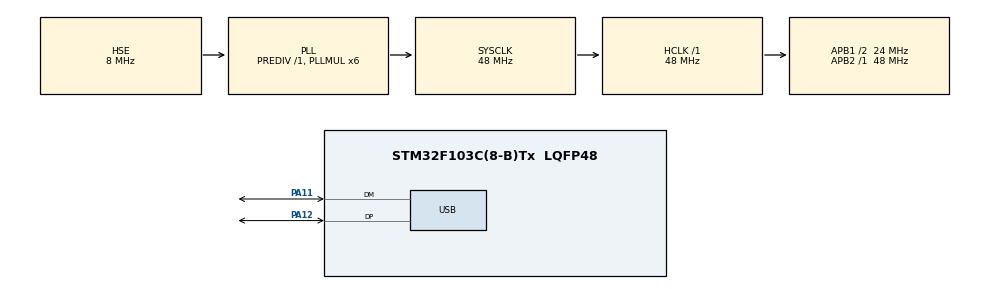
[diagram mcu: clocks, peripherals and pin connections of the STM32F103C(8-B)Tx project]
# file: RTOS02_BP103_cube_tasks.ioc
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Mcu.Family=STM32F1
USB_DEVICE.CLASS_NAME_FS=CDC
PD1-OSC_OUT.Mode=HSE-External-Oscillator
USB_DEVICE.VirtualModeFS=Cdc_FS
PA11.Mode=Device
PD0-OSC_IN.Signal=RCC_OSC_IN
RCC.APB1CLKDivider=RCC_HCLK_DIV2
VP_SYS_VS_ND.Mode=No_Debug
RCC.SYSCLKSource=RCC_SYSCLKSOURCE_PLLCLK
ProjectManager.StackSize=0x400
PD1-OSC_OUT.Signal=RCC_OSC_OUT
PA12.Signal=USB_DP
VP_SYS_VS_tim3.Mode=TIM3
ProjectManager.TargetToolchain=STM32CubeIDE
RCC.HCLKFreq_Value=48000000
VP_USB_DEVICE_VS_USB_DEVICE_CDC_FS.Mode=CDC_FS
RCC.APB2TimFreq_Value=48000000
RCC.USBFreq_Value=48000000
RCC.AHBFreq_Value=48000000
PD0-OSC_IN.Mode=HSE-External-Oscillator
board=custom
RCC.PLLMUL=RCC_PLL_MUL6
NVIC.TIM3_IRQn=true\:0\:0\:false\:false\:true\:false\:true
RCC.APB2Freq_Value=48000000
NVIC.USB_LP_CAN1_RX0_IRQn=true\:0\:0\:false\:false\:true\:false\:true
Mcu.Name=STM32F103C(8-B)Tx
RCC.SYSCLKFreq_VALUE=48000000
Mcu.Package=LQFP48
NVIC.TimeBase=TIM3_IRQn
PA12.Mode=Device
PA11.Signal=USB_DM
NVIC.TimeBaseIP=TIM3
ProjectManager.HeapSize=0x200
NVIC.PriorityGroup=NVIC_PRIORITYGROUP_4
RCC.APB1TimFreq_Value=48000000
RCC.APB1Freq_Value=24000000
USB_DEVICE.VirtualMode=Cdc

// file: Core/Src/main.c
/* USER CODE BEGIN Header */
/**
  ******************************************************************************
  * @file           : main.c
  * @brief          : Main program body
  ******************************************************************************
  * @attention
  *
  * <h2><center>&copy; Copyright (c) 2021 STMicroelectronics.
  * All rights reserved.</center></h2>
  *
  * This software component is licensed by ST under BSD 3-Clause license,
  * the "License"; You may not use this file except in compliance with the
  * License. You may obtain a copy of the License at:
  *                        opensource.org/licenses/BSD-3-Clause
  *
  ******************************************************************************
  */
/* USER CODE END Header */
#include "main.h"
#include "usb_device.h"

/* USER CODE BEGIN Includes */
//#include <stdio.h>
#include "FreeRTOS.h"
#include "task.h"

/* USER CODE END Includes */

void SystemClock_Config(void);
static void MX_GPIO_Init(void);
/* USER CODE BEGIN PFP */

static void task1_handler(void* parameter);
static void task2_handler(void* parameter);
//extern void initialise_monitor_handles(void);

/* USER CODE END PFP */

int main(void)
{
  /* USER CODE BEGIN 1 */

	TaskHandle_t task1_handle;
	TaskHandle_t task2_handle;

	BaseType_t status;

  /* USER CODE END 1 */

  /* MCU Configuration--------------------------------------------------------*/

  /* Reset of all peripherals, Initializes the Flash interface and the Systick. */
  HAL_Init();

  /* Configure the system clock */
  SystemClock_Config();

  /* Initialize all configured peripherals */
  MX_GPIO_Init();
  MX_USB_DEVICE_Init();
  /* USER CODE BEGIN 2 */

//  initialise_monitor_handles();

  status = xTaskCreate(task1_handler, "Task-1", 200, "Task-1\n", 2, &task1_handle);

  configASSERT(status == pdPASS);

  status = xTaskCreate(task2_handler, "Task-2", 200, "Task-2\n", 2, &task2_handle);

  configASSERT(status == pdPASS);

  vTaskStartScheduler();

  // if the control comes here, then the launch of the
  // scheduler has failed due to insufficient memory

  /* USER CODE END 2 */

  /* Infinite loop */
  while (1)
  {

  }
}

void SystemClock_Config(void)
{
  RCC_OscInitTypeDef RCC_OscInitStruct = {0};
  RCC_ClkInitTypeDef RCC_ClkInitStruct = {0};
  RCC_PeriphCLKInitTypeDef PeriphClkInit = {0};

  /** Initializes the RCC Oscillators according to the specified parameters
  * in the RCC_OscInitTypeDef structure.
  */
  RCC_OscInitStruct.OscillatorType = RCC_OSCILLATORTYPE_HSE;
  RCC_OscInitStruct.HSEState = RCC_HSE_ON;
  RCC_OscInitStruct.HSEPredivValue = RCC_HSE_PREDIV_DIV1;
  RCC_OscInitStruct.HSIState = RCC_HSI_ON;
  RCC_OscInitStruct.PLL.PLLState = RCC_PLL_ON;
  RCC_OscInitStruct.PLL.PLLSource = RCC_PLLSOURCE_HSE;
  RCC_OscInitStruct.PLL.PLLMUL = RCC_PLL_MUL6;
  if (HAL_RCC_OscConfig(&RCC_OscInitStruct) != HAL_OK)
  {
    Error_Handler();
  }
  /** Initializes the CPU, AHB and APB buses clocks
  */
  RCC_ClkInitStruct.ClockType = RCC_CLOCKTYPE_HCLK|RCC_CLOCKTYPE_SYSCLK
                              |RCC_CLOCKTYPE_PCLK1|RCC_CLOCKTYPE_PCLK2;
  RCC_ClkInitStruct.SYSCLKSource = RCC_SYSCLKSOURCE_PLLCLK;
  RCC_ClkInitStruct.AHBCLKDivider = RCC_SYSCLK_DIV1;
  RCC_ClkInitStruct.APB1CLKDivider = RCC_HCLK_DIV2;
  RCC_ClkInitStruct.APB2CLKDivider = RCC_HCLK_DIV1;

  if (HAL_RCC_ClockConfig(&RCC_ClkInitStruct, FLASH_LATENCY_1) != HAL_OK)
  {
    Error_Handler();
  }
  PeriphClkInit.PeriphClockSelection = RCC_PERIPHCLK_USB;
  PeriphClkInit.UsbClockSelection = RCC_USBCLKSOURCE_PLL;
  if (HAL_RCCEx_PeriphCLKConfig(&PeriphClkInit) != HAL_OK)
  {
    Error_Handler();
  }
}

static void MX_GPIO_Init(void)
{

  /* GPIO Ports Clock Enable */
  __HAL_RCC_GPIOD_CLK_ENABLE();
  __HAL_RCC_GPIOA_CLK_ENABLE();

}

/* USER CODE BEGIN 4 */

static void task1_handler(void* parameter)
{
	while(1)
	{
//		printf("%s\n", (char*)parameter);
		CDC_Transmit_FS(parameter, 7);
	}

}

static void task2_handler(void* parameter)
{
	while(1)
	{
//		printf("%s\n", (char*)parameter);
		CDC_Transmit_FS(parameter, 7);
	}
}

/* USER CODE END 4 */

 /**
  * @brief  Period elapsed callback in non blocking mode
  * @note   This function is called  when TIM3 interrupt took place, inside
  * HAL_TIM_IRQHandler(). It makes a direct call to HAL_IncTick() to increment
  * a global variable "uwTick" used as application time base.
  * @param  htim : TIM handle
  * @retval None
  */
void HAL_TIM_PeriodElapsedCallback(TIM_HandleTypeDef *htim)
{
  if (htim->Instance == TIM3) {
    HAL_IncTick();
  }
}

void Error_Handler(void)
{
  __disable_irq();
  while (1)
  {
  }
}

/************************ (C) COPYRIGHT STMicroelectronics *****END OF FILE****/
